# STM32U599 register map
File version: 0.2
CPU: CM33 r0p1, little endian, MPU, FPU, 4 interrupt priority bits
Registers are 32-bit, read-write, reset 0x0 unless marked. A register's access mark holds for its fields unless they carry their own. Offsets are from the block's base; [hi:lo] are bit positions; {n}, {i} and the like mark numbered series.

## DCACHE1
Base 0x40031400
Same registers: DCACHE2 0x40031800, SEC_DCACHE1 0x50031400, SEC_DCACHE2 0x50031800
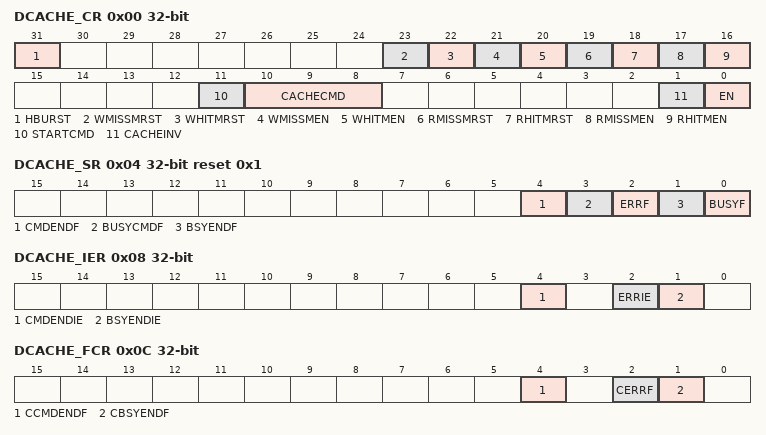
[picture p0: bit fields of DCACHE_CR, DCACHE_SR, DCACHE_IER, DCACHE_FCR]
0x00 DCACHE_CR access per field — DCACHE control register
  [31] HBURST rw, [23] WMISSMRST rw, [22] WHITMRST rw, [21] WMISSMEN rw, [20] WHITMEN rw, [19] RMISSMRST rw, [18] RHITMRST rw, [17] RMISSMEN rw, [16] RHITMEN rw, [11] STARTCMD wo, [10:8] CACHECMD rw, [1] CACHEINV wo, [0] EN rw
0x04 DCACHE_SR ro reset 0x1 — DCACHE status register
  [4] CMDENDF, [3] BUSYCMDF, [2] ERRF, [1] BSYENDF, [0] BUSYF
0x08 DCACHE_IER — DCACHE interrupt enable register
  [4] CMDENDIE, [2] ERRIE, [1] BSYENDIE
0x0C DCACHE_FCR wo — DCACHE flag clear register
  [4] CCMDENDF, [2] CERRF, [1] CBSYENDF
0x10 DCACHE_RHMONR ro — DCACHE read-hit monitor register
  [31:0] RHITMON
0x14 DCACHE_RMMONR ro — DCACHE read-miss monitor register
  [15:0] MRISSMON — RMISSMON
0x20 DCACHE_WHMONR ro — write-hit monitor register
  [31:0] WHITMON
0x24 DCACHE_WMMONR ro — write-miss monitor register
  [15:0] WMISSMON
0x28 DCACHE_CMDRSADDRR — command range start address register
  [31:4] CMDSTARTADDR
0x2C DCACHE_CMDREADDRR — command range start address register
  [31:4] CMDENDADDR

## DCMI — Digital camera interface
Base 0x4202C000
Same registers: SEC_DCMI 0x5202C000
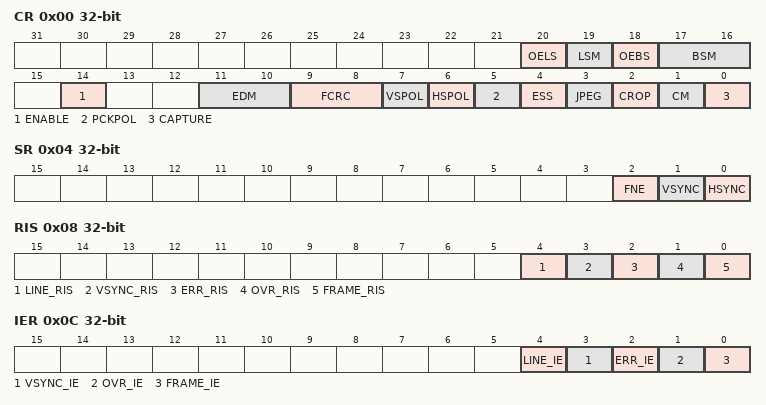
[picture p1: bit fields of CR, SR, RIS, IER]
0x00 CR — control register
  [20] OELS — Odd/Even Line Select (Line Select Start)
  [19] LSM — Line Select mode
  [18] OEBS — Odd/Even Byte Select (Byte Select Start)
  [17:16] BSM — Byte Select mode
  [14] ENABLE — DCMI enable
  [11:10] EDM — Extended data mode
  [9:8] FCRC — Frame capture rate control
  [7] VSPOL — Vertical synchronization polarity
  [6] HSPOL — Horizontal synchronization polarity
  [5] PCKPOL — Pixel clock polarity
  [4] ESS — Embedded synchronization select
  [3] JPEG — JPEG format
  [2] CROP — Crop feature
  [1] CM — Capture mode
  [0] CAPTURE — Capture enable
0x04 SR ro — status register
  [2] FNE — FIFO not empty
  [1] VSYNC — Vertical synchronization
  [0] HSYNC — Horizontal synchronization
0x08 RIS ro — raw interrupt status register
  [4] LINE_RIS — Line raw interrupt status
  [3] VSYNC_RIS — DCMI_VSYNC raw interrupt status
  [2] ERR_RIS — Synchronization error raw interrupt status
  [1] OVR_RIS — Overrun raw interrupt status
  [0] FRAME_RIS — Capture complete raw interrupt status
0x0C IER — interrupt enable register
  [4] LINE_IE — Line interrupt enable
  [3] VSYNC_IE — DCMI_VSYNC interrupt enable
  [2] ERR_IE — Synchronization error interrupt enable
  [1] OVR_IE — Overrun interrupt enable
  [0] FRAME_IE — Capture complete interrupt enable
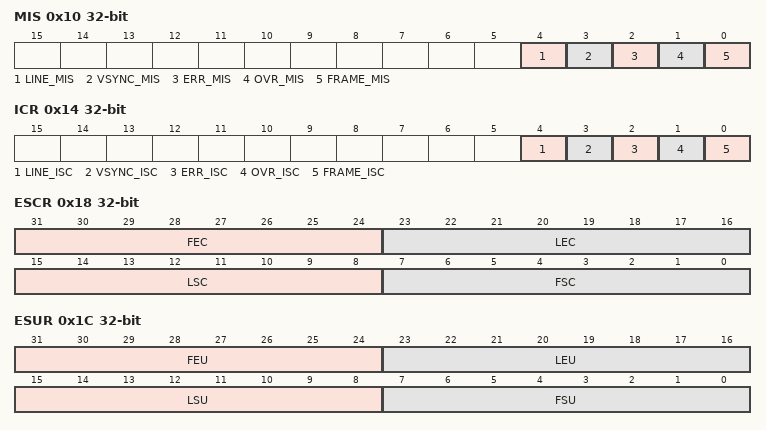
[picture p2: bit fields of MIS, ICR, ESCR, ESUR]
0x10 MIS ro — masked interrupt status register
  [4] LINE_MIS — Line masked interrupt status
  [3] VSYNC_MIS — VSYNC masked interrupt status
  [2] ERR_MIS — Synchronization error masked interrupt status
  [1] OVR_MIS — Overrun masked interrupt status
  [0] FRAME_MIS — Capture complete masked interrupt status
0x14 ICR wo — interrupt clear register
  [4] LINE_ISC — line interrupt status clear
  [3] VSYNC_ISC — Vertical Synchronization interrupt status clear
  [2] ERR_ISC — Synchronization error interrupt status clear
  [1] OVR_ISC — Overrun interrupt status clear
  [0] FRAME_ISC — Capture complete interrupt status clear
0x18 ESCR — background offset register
  [31:24] FEC — Frame end delimiter code
  [23:16] LEC — Line end delimiter code
  [15:8] LSC — Line start delimiter code
  [7:0] FSC — Frame start delimiter code
0x1C ESUR — embedded synchronization unmask register
  [31:24] FEU — Frame end delimiter unmask
  [23:16] LEU — Line end delimiter unmask
  [15:8] LSU — Line start delimiter unmask
  [7:0] FSU — Frame start delimiter unmask
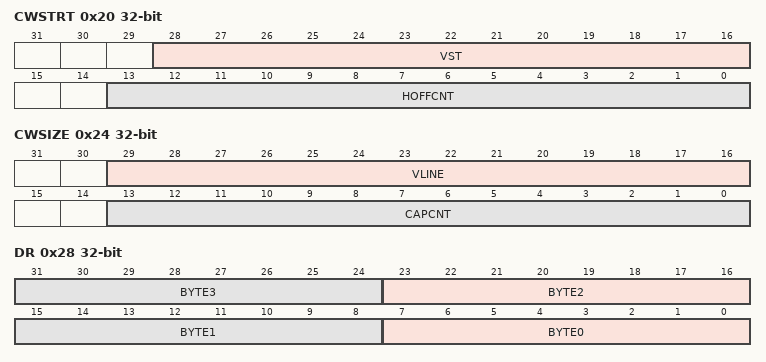
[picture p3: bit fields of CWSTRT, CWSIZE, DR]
0x20 CWSTRT — crop window start
  [28:16] VST — Vertical start line count
  [13:0] HOFFCNT — Horizontal offset count
0x24 CWSIZE — crop window size
  [29:16] VLINE — Vertical line count
  [13:0] CAPCNT — Capture count
0x28 DR ro — data register
  [8n+7:8n] BYTE{n} (n=0..3) — Data byte {n}
